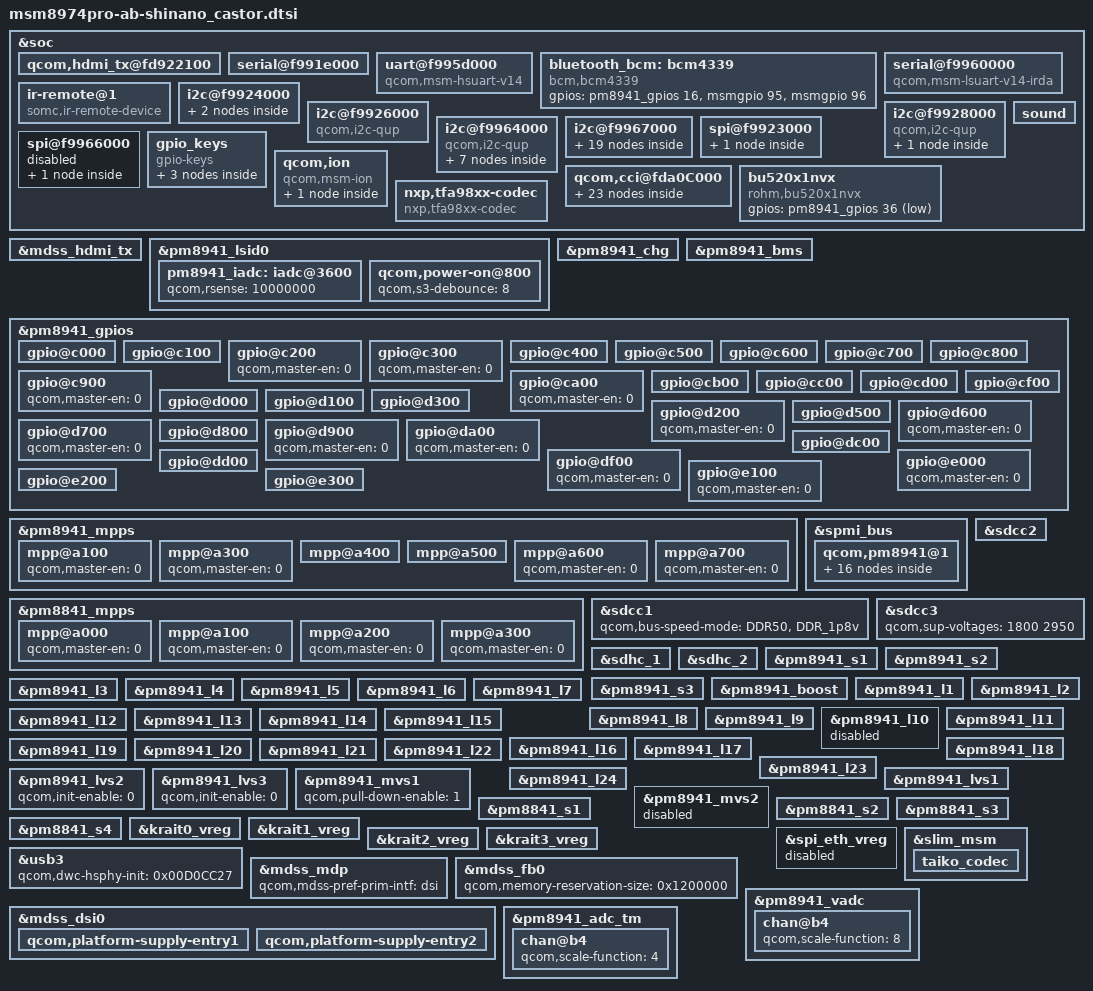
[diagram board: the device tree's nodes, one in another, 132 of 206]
/* arch/arm/boot/dts/msm8974pro-ab-shinano_castor.dtsi
 *
 * Copyright (C) 2013-2014 Sony Mobile Communications AB.
 *
 * Author: Shougo Watanabe <Shougo.X.Watanabe@sonymobile.com>
 *
 * This program is free software; you can redistribute it and/or modify
 * it under the terms of the GNU General Public License version 2 and
 * only version 2 as published by the Free Software Foundation.
 *
 * This program is distributed in the hope that it will be useful,
 * but WITHOUT ANY WARRANTY; without even the implied warranty of
 * MERCHANTABILITY or FITNESS FOR A PARTICULAR PURPOSE.  See the
 * GNU General Public License for more details.
 */

&soc {
	qcom,hdmi_tx@fd922100 {
		status = "ok";
	};

	/* UART : BLSP2 */
	serial@f991e000 {
		status = "ok";
	};

	/* UART : BLSP7 */
	uart@f995d000 {
		compatible = "qcom,msm-hsuart-v14";
		reg = <0xf995d000 0x1000>,
		<0xf9944000 0x19000>;
		reg-names = "core_mem", "bam_mem";
		interrupt-names = "core_irq", "bam_irq", "wakeup_irq";
		#address-cells = <0>;
		interrupt-parent = <&uart7>;
		interrupts = <0 1 2>;
		#interrupt-cells = <1>;
		interrupt-map-mask = <0xffffffff>;
		interrupt-map = <0 &intc 0 113 0
				 1 &intc 0 239 0
				 2 &msmgpio 42 0>;
		qcom,bam-tx-ep-pipe-index = <0>;
		qcom,bam-rx-ep-pipe-index = <1>;
		status = "ok";
	};

	bluetooth_bcm: bcm4339 {
		compatible = "bcm,bcm4339";
		gpios = <&pm8941_gpios 16 0>, /* BT_REG_ON */
			<&msmgpio 95 0>, /* BT_HOST_WAKE */
			<&msmgpio 96 0>; /* BT_DEV_WAKE */
	};

	/* UART : BLSP10 */
	serial@f9960000 {
		compatible = "qcom,msm-lsuart-v14-irda";
		reg = <0xf9960000 0x1000>;
		interrupts = <0 116 0>;
		qcom,config-gpio = <1>;
		qcom,tx-gpio = <&msmgpio 53 0x00>;
		qcom,rx-gpio = <&msmgpio 54 0x00>;
		status = "ok";
	};

	ir-remote@1 {
		compatible = "somc,ir-remote-device";
		reg = <0x1>;
		ir_remote_en = <&pm8941_mpps 5 0x00>;
		status = "ok";
	};

	/* I2C : BLSP2 */
	i2c@f9924000 {
		cell-index = <2>;
		qcom,i2c-bus-freq = <355000>;
		status = "ok";
		synaptics@20 {
			status = "disabled";
		};
		atmel_mxt_ts@4a {
			status = "disabled";
		};
	};

	/* I2C : BLSP4 */
	i2c@f9926000 {
		cell-index = <4>;
		compatible = "qcom,i2c-qup";
		reg = <0xf9926000 0x1000>;
		#address-cells = <1>;
		#size-cells = <0>;
		reg-names = "qup_phys_addr";
		interrupts = <0 98 0>;
		interrupt-names = "qup_err_intr";
		qcom,i2c-bus-freq = <355000>;
		qcom,i2c-src-freq = <50000000>;
		qcom,master-id = <86>;
		status = "ok";
	};

	/* I2C : BLSP6 */
	i2c@f9928000 {
		cell-index = <6>;
		compatible = "qcom,i2c-qup";
		reg = <0xf9928000 0x1000>;
		#address-cells = <1>;
		#size-cells = <0>;
		reg-names = "qup_phys_addr";
		interrupts = <0 100 0>;
		interrupt-names = "qup_err_intr";
		qcom,i2c-bus-freq = <355000>;
		qcom,i2c-src-freq = <50000000>;
		qcom,master-id = <86>;
		status = "ok";
		nfc@28 {
			compatible = "nxp,pn547";
			reg = <0x28>;
			interrupt-parent = <&msmgpio>;
			interrupts = <24 0x1>;
			nxp,pvdd_en = <&pm8941_gpios 34 0x01>;
			nxp,irq_gpio = <&msmgpio 24 0x00>;
			nxp,dwld_en = <&msmgpio 57 0x00>;
			nxp,ven = <&pm8941_mpps 2 0x01>;
			dynamic_config;
			configure_gpio = <&pm8941_gpios 33 0x00>;
			configure_mpp = <&pm8941_mpps 2 0x00>;
		};
	};

	/* I2C : BLSP8 */
	i2c@f9964000 {
		cell-index = <8>;
		compatible = "qcom,i2c-qup";
		reg = <0xf9964000 0x1000>;
		#address-cells = <1>;
		#size-cells = <0>;
		reg-names = "qup_phys_addr";
		interrupts = <0 102 0>;
		interrupt-names = "qup_err_intr";
		qcom,i2c-bus-freq = <355000>;
		qcom,i2c-src-freq = <50000000>;
		qcom,scl-gpio = <&msmgpio 48 0x00>;
		qcom,sda-gpio = <&msmgpio 47 0x00>;
		qcom,master-id = <84>;
		status = "ok";
		synaptics_clearpad@2c {
			compatible = "synaptics,clearpad";
			reg = <0x2c>;
			interrupt-parent = <&msmgpio>;
			interrupts = <86 0x2>;
			touch_vdd-supply = <&pm8941_l22>;
			touch_vio-supply = <&pm8941_lvs3>;
			synaptics,irq_gpio = <&msmgpio 86 0x00>;
			chip_id = <0x37>;
			num_sensor_rx = <46>;
			num_sensor_tx = <26>;
			pen_enabled = <0>;
			glove_enabled = <0>;
			touch_pressure_enabled = <1>;
			touch_size_enabled = <0>;
			touch_orientation_enabled = <0>;
			preset_x_max = <1919>;
			preset_y_max = <1199>;
			preset_n_fingers = <10>;
			por_delay_after = <200>;
			large_panel;
			wakeup_gesture_support = <1>;
			wakeup_gesture_timeout = <2000>;
			wakeup_gesture {
				double_tap {
					gesture_code = <0x0001>;
					event_00 {
						type = <2>; /* LOG */
						message = "=== DOUBLE TAP ===";
					};
					event_01 {
						type = <1>; /* KEY */
						code = <116>; /* KEY_POWER */
						down = <1>;
					};
					event_02 {
						type = <1>; /* KEY */
						code = <116>; /* KEY_POWER */
						down = <0>;
					};
					event_03 {
						type = <99>; /* END */
					};
				};
			};
		};
	};

	/* I2C : BLSP11 */
	i2c@f9967000 {
		cell-index = <11>;
		qcom,i2c-bus-freq = <355000>;
		qcom,scl-gpio = <&msmgpio 84 0x00>;
		qcom,sda-gpio = <&msmgpio 83 0x00>;
		status = "ok";
		tfa98xx_top@68 {
			compatible = "nxp,tfa98xx_top";
			reg = <0x68>;
		};
		tfa98xx_bottom@6A {
			compatible = "nxp,tfa98xx_bottom";
			reg = <0x6A>;
		};
		sii8620@72 {
			compatible = "qcom,mhl-sii8620";
			reg = <0x72>;
			interrupt-parent = <&msmgpio>;
			mhl-intr-gpio = <&msmgpio 64 0>;
			mhl-pwr-gpio = <&msmgpio 23 0>;
			mhl-rst-gpio = <&msmgpio 16 0>;
			qcom,hdmi-tx-map = <&mdss_hdmi_tx>;
			mhl-switch-sel-1-gpio = <&msmgpio 10 0>;
			mhl-switch-sel-2-gpio = <&msmgpio 11 0>;
			mhl-fw-wake-gpio =  <&msmgpio 31 0>;
		};
		ti_lp855x@2c {
			compatible = "Texas Instruments,lp855x";
			reg = <0x2c>;
			status = "ok";
			bl_enable = <&msmgpio 69 0>;
			linux,name = "lp8556";
			linux,default-trigger = "bkl-trigger";
			mode = "register based";
			chip_name = "lp8556";
			max_br = <0xff>;
			init_br = <0x3f>;
			cfg3_reg = <0x5e>;
			eprom@98 {
				addr = <0x98>;
				data = <0x16>;
			};
			eprom@9e {
				addr = <0x9e>;
				data = <0x22>;
			};
			eprom@a0 {
				addr = <0xa0>;
				data = <0xff>;
			};
			eprom@a1 {
				addr = <0xa1>;
				data = <0x3f>;
			};
			eprom@a2 {
				addr = <0xa2>;
				data = <0x20>;
			};
			eprom@a4 {
				addr = <0xa4>;
				data = <0x72>;
			};
			eprom@a5 {
				addr = <0xa5>;
				data = <0x04>;
			};
			eprom@a6 {
				addr = <0xa6>;
				data = <0x80>;
			};
			eprom@a7 {
				addr = <0xa7>;
				data = <0xf7>;
			};
			eprom@a8 {
				addr = <0xa8>;
				data = <0x24>;
			};
			eprom@a9 {
				addr = <0xa9>;
				data = <0x80>;
			};
			eprom@aa {
				addr = <0xaa>;
				data = <0x0f>;
			};
			eprom@ae {
				addr = <0xae>;
				data = <0x0f>;
			};
		};
		isa1200@48 {
			status = "disabled";
		};
		ad7146@2f {
			compatible = "AD,ad7146";
			interrupt-parent = <&spmi_bus>;
			reg = <0x2f 0>;
			interrupts = <0x0 0xc8 0x0>; /* PM8941 GPIO 9 */
			interrupt-name = "ad7146_irq_gpio";
			prox_vdd-supply = <&pm8941_l19>;
			prox_vdd-supply_name = "prox_vdd";
			AD,irq_gpio = <&pm8941_gpios 9 0x00>;
			pad,stage0-connect1 = <0x3FBF>;
			pad,stage0-connect2 = <0x1FDF>;
			pad,stage0-afe = <0x0100>;
			pad,stage0-sensitivity = <0x5454>;
			pad,stage0-offset_l = <0x000A>;
			pad,stage0-offset_h = <0x0018>;
			pad,stage0-offset_l_clamp = <0x0018>;
			pad,stage0-offset_h_clamp = <0x000A>;
			pad,stage1-connect1 = <0x37FF>;
			pad,stage1-connect2 = <0x1BFF>;
			pad,stage1-afe = <0x1200>;
			pad,stage1-sensitivity = <0x5454>;
			pad,stage1-offset_l = <0x000A>;
			pad,stage1-offset_h = <0x0070>;
			pad,stage1-offset_l_clamp = <0x0070>;
			pad,stage1-offset_h_clamp = <0x000A>;
			status = "ok";
		};
	};

	/* SPI : BLSP1 */
	spi@f9923000 {
		cs-gpios = <&msmgpio 2 0>;
		spi-max-frequency = <38400000>;
		status = "ok";
		ethernet-switch@2 {
			status = "disabled";
		};
	};

	/* SPI : BLSP10 */
	spi@f9966000 {
		status = "disabled";
		epm-adc@0 {
			status = "disabled";
		};
	};

	gpio_keys {
		compatible = "gpio-keys";
		input-name = "gpio-keys";
		interrupt-parent = <&msmgpio>;
		interrupts = <9 0>;

		vol_dn {
			label = "volume_down";
			gpios = <&pm8941_gpios 2 0x1>;
			linux,input-type = <1>;
			linux,code = <114>;
			gpio-key,wakeup;
			debounce-interval = <15>;
		};

		vol_up {
			label = "volume_up";
			gpios = <&pm8941_gpios 5 0x1>;
			linux,input-type = <1>;
			linux,code = <115>;
			gpio-key,wakeup;
			debounce-interval = <15>;
		};

		sim_det {
			label = "sim-detection";
			gpios = <&msmgpio 9 0x0>;
			linux,input-type = <5>;
			linux,code = <7>;
			gpio-key,wakeup;
			debounce-interval = <10>;
		};
	};

	qcom,cci@fda0C000 {
		qcom,cci-master0 {
			qcom,hw-thigh = <22>;
			qcom,hw-tlow = <33>;
		};

		qcom,cci-master1 {
			qcom,hw-thigh = <22>;
			qcom,hw-tlow = <33>;
		};

		qcom,camera@20 {
			compatible = "qcom,sony_camera_0";
			reg = <0x20 0x0>;
			status = "ok";
			qcom,slave-id = <0x20 0x0 0x0000>;
			qcom,csiphy-sd-index = <0>;
			qcom,csid-sd-index = <0>;
			qcom,mount-angle = <270>;
			qcom,sensor-name = "sony_camera_0";
			cam_vdig-supply = <&pm8941_l3>;
			cam_vana-supply = <&pm8941_l17>;
			cam_vio-supply = <&pm8941_lvs2>;
			cam_vaf-supply = <&pm8941_l23>;
			qcom,cam-vreg-name = "cam_vdig", "cam_vana", "cam_vio",
					     "cam_vaf";
			qcom,cam-vreg-type = <0 0 1 0>;
			qcom,cam-vreg-min-voltage = <1200000 2700000 0 2800000>;
			qcom,cam-vreg-max-voltage = <1200000 2700000 0 2800000>;
			qcom,cam-vreg-op-mode = <105000 85600 0 300000>;
			qcom,gpio-no-mux = <0>;
			gpios = <&msmgpio 15 0>,
				<&msmgpio 94 0>;
			qcom,gpio-reset = <1>;
			qcom,gpio-req-tbl-num = <0 1>;
			qcom,gpio-req-tbl-flags = <1 0>;
			qcom,gpio-req-tbl-label = "CAMIF_MCLK",
						  "CAM_RESET1";
			qcom,gpio-set-tbl-num = <1 1>;
			qcom,gpio-set-tbl-flags = <0 2>;
			qcom,gpio-set-tbl-delay = <1 1000>;
			qcom,csi-lane-assign = <0x4320>;
			qcom,csi-lane-mask = <0x1F>;
			qcom,sensor-position = <0>;
			qcom,sensor-mode = <1>;
			qcom,cci-master = <0>;
			sony,i2c_addr = <0x20>;
			sony,eeprom_addr = <0xA0>;
			sony,eeprom_type = <0>;
			sony,eeprom_max_len = <2048>;
			sony,gpio_af = <0>;
			sony,subdev_code = <0x3007>;

			sony,camera_modules {
				module_names = "GENERIC", "SOI08BS2";
				default_module_name = "SOI08BS2";

				GENERIC {
					mount_angle = <180>;
					sensor_rotation = <180>;
					sensor_facing = <0>;
					has_3a = <0>;
					pll_num = <18>;
					pll = <674 674 674 674 674 674 674 674 674 674 674 674 674 674 674 674 674 674>;
					power_off {
						commands =
								"I2C_WRITE",
								"GPIO_RESET",
								"CAM_CLK",
								"CAM_VDIG",
								"CAM_VIO",
								"CAM_VANA",
								"CAM_VAF",
								"EXIT";
						CAM_VDIG =
							<0 0xFFFFFFFF 0 1>;
						CAM_VIO = <1 0xFFFFFFFF 0 1>;
						CAM_VANA =
							<2 0xFFFFFFFF 0 1>;
						CAM_VAF = <3 0xFFFFFFFF 0 99>;
						GPIO_RESET = <5 0x0 0 1>;
						CAM_CLK = <6 0xFFFFFFFF 0 1>;
						I2C_WRITE = <7 0x0100 0 100>;
						EXIT = <8 0x0 0 0>;
					};
					power_on {
						commands =
								"CAM_VDIG",
								"CAM_VIO",
								"CAM_VANA",
								"CAM_VAF",
								"GPIO_RESET",
								"CAM_CLK",
								"EXIT";
						CAM_VDIG = <0 1200 85000 1>;
						CAM_VIO = <1 0 0 1>;
						CAM_VANA = <2 2700 103000 1>;
						CAM_VAF = <3 2800 106500 1>;
						GPIO_RESET = <5 1 0 1>;
						CAM_CLK = <6 0 0 1>;
						EXIT = <8 0x0 0 0>;
					};
				};
				SOI08BS2 {
					mount_angle = <180>;
					sensor_rotation = <180>;
					sensor_facing = <0>;
					has_3a = <0>;
					pll_num = <18>;
					pll = <674 674 674 674 674 674 674 674 674 674 674 674 674 674 674 674 674 674>;
					power_off {
						commands =
								"I2C_WRITE",
								"GPIO_RESET",
								"CAM_CLK",
								"CAM_VDIG",
								"CAM_VIO",
								"CAM_VANA",
								"CAM_VAF",
								"EXIT";
						CAM_VDIG =
							<0 0xFFFFFFFF 0 1>;
						CAM_VIO = <1 0xFFFFFFFF 0 1>;
						CAM_VANA =
							<2 0xFFFFFFFF 0 1>;
						CAM_VAF = <3 0xFFFFFFFF 0 99>;
						GPIO_RESET = <5 0x0 0 1>;
						CAM_CLK = <6 0xFFFFFFFF 0 1>;
						I2C_WRITE = <7 0x0100 0 100>;
						EXIT = <8 0x0 0 0>;
					};
					power_on {
						commands =
								"CAM_VDIG",
								"CAM_VIO",
								"CAM_VANA",
								"CAM_VAF",
								"GPIO_RESET",
								"CAM_CLK",
								"EXIT";
						CAM_VDIG = <0 1200 85000 1>;
						CAM_VIO = <1 0 0 1>;
						CAM_VANA = <2 2700 103000 1>;
						CAM_VAF = <3 2800 106500 1>;
						GPIO_RESET = <5 1 0 1>;
						CAM_CLK = <6 0 0 1>;
						EXIT = <8 0x0 0 0>;
					};
				};
			};
		};

		qcom,camera@6c {
			compatible = "qcom,sony_camera_1";
			reg = <0x6c 0x0>;
			status = "ok";
			qcom,slave-id = <0x6c 0x0000 0x0000>;
			qcom,csiphy-sd-index = <2>;
			qcom,csid-sd-index = <2>;
			qcom,mount-angle = <270>;
			qcom,sensor-name = "sony_camera_1";
			cam_vdig-supply = <&pm8941_l3>;
			cam_vana-supply = <&pm8941_l17>;
			cam_vio-supply = <&pm8941_lvs2>;
			qcom,cam-vreg-name = "cam_vdig", "cam_vana", "cam_vio";
			qcom,cam-vreg-type = <0 0 1>;
			qcom,cam-vreg-min-voltage = <1200000 2700000 0>;
			qcom,cam-vreg-max-voltage = <1200000 2700000 0>;
			qcom,cam-vreg-op-mode = <105000 85600 0>;
			qcom,gpio-no-mux = <0>;
			gpios = <&msmgpio 17 0>,
				<&msmgpio 18 0>;
			qcom,gpio-reset = <1>;
			qcom,gpio-req-tbl-num = <0 1>;
			qcom,gpio-req-tbl-flags = <1 0>;
			qcom,gpio-req-tbl-label = "CAMIF_MCLK",
						  "CAM_RESET1";
			qcom,gpio-set-tbl-num = <1 1>;
			qcom,gpio-set-tbl-flags = <0 2>;
			qcom,gpio-set-tbl-delay = <1 1000>;
			qcom,csi-lane-assign = <0x4320>;
			qcom,csi-lane-mask = <0x7>;
			qcom,sensor-position = <1>;
			qcom,sensor-mode = <1>;
			qcom,cci-master = <1>;
			sony,i2c_addr = <0x6c>;
			sony,eeprom_addr = <0xA0>;
			sony,eeprom_type = <0>;
			sony,eeprom_max_len = <1024>;
			sony,gpio_af = <0>;
			sony,subdev_code = <0x3007>;

			sony,camera_modules {
				module_names = "GENERIC", "LGI02BN1",
						"SEM02BN1";
				default_module_name = "SEM02BN1";

				GENERIC {
					mount_angle = <0>;
					sensor_rotation = <0>;
					sensor_facing = <1>;
					has_3a = <0>;
					pll_num = <18>;
					pll = <104 104 104 104 104 104 104 104 104 104 104 104 104 104 104 104 104 104>;
					power_off {
						commands =
								"I2C_WRITE",
								"GPIO_RESET",
								"CAM_CLK",
								"CAM_VANA",
								"CAM_VIO",
								"CAM_VDIG",
								"EXIT";
						CAM_VDIG =
							<0 0xFFFFFFFF 0 98>;
						CAM_VIO = <1 0xFFFFFFFF 0 1>;
						CAM_VANA =
							<2 0xFFFFFFFF 0 1>;
						GPIO_RESET = <5 0x0 0 1>;
						CAM_CLK = <6 0xFFFFFFFF 0 1>;
						I2C_WRITE = <7 0x0100 0 100>;
						EXIT = <8 0x0 0 0>;
					};
					power_on {
						commands =
								"CAM_VDIG",
								"CAM_VIO",
								"CAM_VANA",
								"GPIO_RESET",
								"CAM_CLK",
								"EXIT";
						CAM_VDIG = <0 1200 85000 1>;
						CAM_VIO = <1 0 0 1>;
						CAM_VANA = <2 2700 103000 1>;
						GPIO_RESET = <5 1 0 1>;
						CAM_CLK = <6 0 0 1>;
						EXIT = <8 0x0 0 0>;
					};
				};
				LGI02BN1 {
					mount_angle = <0>;
					sensor_rotation = <0>;
					sensor_facing = <1>;
					has_3a = <0>;
					pll_num = <18>;
					pll = <104 104 104 104 104 104 104 104 104 104 104 104 104 104 104 104 104 104>;
					power_off {
						commands =
								"I2C_WRITE",
								"GPIO_RESET",
								"CAM_CLK",
								"CAM_VANA",
								"CAM_VIO",
								"CAM_VDIG",
								"EXIT";
						CAM_VDIG =
							<0 0xFFFFFFFF 0 98>;
						CAM_VIO = <1 0xFFFFFFFF 0 1>;
						CAM_VANA =
							<2 0xFFFFFFFF 0 1>;
						GPIO_RESET = <5 0x0 0 1>;
						CAM_CLK = <6 0xFFFFFFFF 0 1>;
						I2C_WRITE = <7 0x0100 0 100>;
						EXIT = <8 0x0 0 0>;
					};
					power_on {
						commands =
								"CAM_VDIG",
								"CAM_VIO",
								"CAM_VANA",
								"GPIO_RESET",
								"CAM_CLK",
								"EXIT";
						CAM_VDIG = <0 1200 85000 1>;
						CAM_VIO = <1 0 0 1>;
						CAM_VANA = <2 2700 103000 1>;
						GPIO_RESET = <5 1 0 1>;
						CAM_CLK = <6 0 0 1>;
						EXIT = <8 0x0 0 0>;
					};
				};
				SEM02BN1 {
					mount_angle = <0>;
					sensor_rotation = <0>;
					sensor_facing = <1>;
					has_3a = <0>;
					pll_num = <18>;
					pll = <104 104 104 104 104 104 104 104 104 104 104 104 104 104 104 104 104 104>;
					power_off {
						commands =
								"I2C_WRITE",
								"GPIO_RESET",
								"CAM_CLK",
								"CAM_VANA",
								"CAM_VIO",
								"CAM_VDIG",
								"EXIT";
						CAM_VDIG =
							<0 0xFFFFFFFF 0 98>;
						CAM_VIO = <1 0xFFFFFFFF 0 1>;
						CAM_VANA =
							<2 0xFFFFFFFF 0 1>;
						GPIO_RESET = <5 0x0 0 1>;
						CAM_CLK = <6 0xFFFFFFFF 0 1>;
						I2C_WRITE = <7 0x0100 0 100>;
						EXIT = <8 0x0 0 0>;
					};
					power_on {
						commands =
								"CAM_VDIG",
								"CAM_VIO",
								"CAM_VANA",
								"GPIO_RESET",
								"CAM_CLK",
								"EXIT";
						CAM_VDIG = <0 1200 85000 1>;
						CAM_VIO = <1 0 0 1>;
						CAM_VANA = <2 2700 103000 1>;
						GPIO_RESET = <5 1 0 1>;
						CAM_CLK = <6 0 0 1>;
						EXIT = <8 0x0 0 0>;
					};
				};
			};
		};

		/* disable Qualcomm camera sensors */
		qcom,camera@6e {
			status = "disabled";
		};

		qcom,camera@90 {
			status = "disabled";
		};
	};

	qcom,ion {
		compatible = "qcom,msm-ion";

		qcom,ion-heap@20 { /* CAMERA HEAP */
			compatible = "qcom,msm-ion-reserve";
			reg = <20>;
			qcom,heap-align = <0x1000>;
			qcom,memory-reservation-type = "EBI1"; /* reserve EBI memory */
			qcom,memory-reservation-size = <0x6400000>;
			qcom,ion-heap-type = "CARVEOUT";
		};
	};

	sound {
		qcom,audio-routing =
			"RX_BIAS", "MCLK",
			"LDO_H", "MCLK",
			"AMIC5", "MCLK",
			"AMIC6", "MCLK",
			"Ext Spk Bottom Pos", "LINEOUT1",
			"Ext Spk Bottom Neg", "LINEOUT3",
			"Ext Spk Top Pos", "LINEOUT2",
			"Ext Spk Top Neg", "LINEOUT4",
			"AMIC1", "MIC BIAS1 External",
			"MIC BIAS1 External", "Secondary Mic",
			"AMIC2", "MIC BIAS2 External",
			"MIC BIAS2 External", "Headset Mic",
			"MIC BIAS2 External", "ANCRight Headset Mic",
			"AMIC3", "MIC BIAS3 External",
			"MIC BIAS3 External", "ANCLeft Headset Mic",
			"AMIC4", "MIC BIAS1 External",
			"MIC BIAS1 External", "Handset Mic";
	};

	bu520x1nvx {
		compatible = "rohm,bu520x1nvx";
		gpios = <&pm8941_gpios 36 0x1>;
	};

	nxp,tfa98xx-codec {
		compatible = "nxp,tfa98xx-codec";
	};
};

&mdss_hdmi_tx {
	/* rhine doesn't use hpd-5v */
	qcom,hdmi-tx-supply-names = "hpd-gdsc", "core-vdda", "core-vcc";
	qcom,hdmi-tx-min-voltage-level = <0 1800000 1800000>;
	qcom,hdmi-tx-max-voltage-level = <0 1800000 1800000>;
	qcom,hdmi-tx-peak-current = <0 300000 0>;
};

&pm8941_lsid0 {
	pm8941_iadc: iadc@3600 {
		qcom,rsense = <10000000>;
	};

	qcom,power-on@800 {
		qcom,s3-debounce = <8>;
	};
};

&pm8941_chg {
	qcom,vddmax-mv = <4350>;
	qcom,vddsafe-mv = <4400>;
	qcom,vinmin-mv = <4200>;
	qcom,ibatmax-ma = <3000>;
	qcom,ibatterm-ma = <300>;
	qcom,ibatsafe-ma = <3000>;
	qcom,maxinput-dc-ma = <1800>;
	qcom,maxinput-dc-mv = <10000>;
	qcom,maxinput-usb-ma = <1500>;
	qcom,maxinput-usb-mv = <13000>;
	qcom,thermal-mitigation = <3000 2500 2000 1500 1100 800 500 300 100 0>;
	qcom,cool-bat-mv = <4350>;
	qcom,ibatmax-warm-ma = <1800>;
	qcom,warm-bat-mv = <4200>;
	qcom,ibatmax-cool-ma = <1800>;
	qcom,vbatdet-delta-mv = <70>;
	qcom,tchg-mins = <512>;
	qcom,vbatweak-mv = <3200>;
};

&pm8941_bms {
	qcom,v-cutoff-uv = <3200000>;
	qcom,max-voltage-uv = <4350000>;
	qcom,r-conn-mohm = <0>;
	qcom,low-soc-calculate-soc-threshold = <5>;
	qcom,low-soc-calculate-soc-ms = <1000>;
	qcom,calculate-soc-ms = <30000>;
	qcom,chg-term-ua = <300000>;
	qcom,use-external-rsense;
	qcom,batt-type = <3>;
	qcom,use-ocv-thresholds;
	qcom,ocv-voltage-high-threshold-uv = <3830000>;
	qcom,ocv-voltage-low-threshold-uv = <3740000>;
	qcom,shutdown-soc-valid-limit = <40>;
	qcom,enable-fcc-learning;
	qcom,min-fcc-learning-soc = <20>;
	qcom,min-fcc-ocv-pc = <30>;
	qcom,min-fcc-learning-samples = <5>;
	qcom,fcc-resolution = <26>;
	qcom,clamp-soc-max-count = <2>;
};

&pm8941_gpios {
	/* GPIO_1: CHG_PATH_PRI */
	gpio@c000 {
		qcom,src-sel = <0>;		/* GPIO */
		qcom,mode = <0>;		/* In */
		qcom,vin-sel = <2>;		/* S3 */
		qcom,pull = <5>;		/* NP */
		qcom,master-en = <1>;		/* Enable */
		status = "ok";
	};

	/* GPIO_2: VOL_DN */
	gpio@c100 {
		qcom,src-sel = <0>;		/* GPIO */
		qcom,mode = <0>;		/* In */
		qcom,vin-sel = <2>;		/* S3 */
		qcom,pull = <0>;		/* PU */
		qcom,master-en = <1>;		/* Enable */
		status = "ok";
	};

	/* GPIO_3: NC */
	gpio@c200 {
		qcom,master-en = <0>;		/* Disable */
		status = "ok";
	};

	/* GPIO_4: NC */
	gpio@c300 {
		qcom,master-en = <0>;		/* Disable */
		status = "ok";
	};

	/* GPIO_5: VOL_UP */
	gpio@c400 {
		qcom,src-sel = <0>;		/* GPIO */
		qcom,mode = <0>;		/* In */
		qcom,vin-sel = <2>;		/* S3 */
		qcom,pull = <0>;		/* PU */
		qcom,master-en = <1>;		/* Enable */
		status = "ok";
	};

	/* GPIO_6: HW_ID_1 */
	gpio@c500 {
		qcom,src-sel = <0>;		/* GPIO */
		qcom,mode = <0>;		/* In */
		qcom,vin-sel = <2>;		/* S3 */
		qcom,pull = <5>;		/* NP */
		qcom,master-en = <1>;		/* Enable */
		status = "ok";
	};

	/* GPIO_7: HW_ID_2 */
	gpio@c600 {
		qcom,src-sel = <0>;		/* GPIO */
		qcom,mode = <0>;		/* In */
		qcom,vin-sel = <2>;		/* S3 */
		qcom,pull = <5>;		/* NP */
		qcom,master-en = <1>;		/* Enable */
		status = "ok";
	};

	/* GPIO_8: RF_LCD_ID_EN */
	gpio@c700 {
		qcom,src-sel = <0>;		/* GPIO */
		qcom,mode = <1>;		/* Out */
		qcom,output-type = <0>;		/* CMOS */
		qcom,vin-sel = <2>;		/* S3 */
		qcom,out-strength = <3>;	/* High */
		qcom,invert = <0>;		/* Low */
		qcom,master-en = <1>;		/* Enable */
		status = "ok";
	};

	/* GPIO_9: P_SENSOR_INT_N */
	gpio@c800 {
		qcom,src-sel = <0>;		/* GPIO */
		qcom,mode = <0>;		/* In */
		qcom,vin-sel = <2>;		/* S3 */
		qcom,pull = <0>;		/* PU */
		qcom,master-en = <1>;		/* Enable */
		status = "ok";
	};

	/* GPIO_10: NC (P_SENSOR_INT2_N) */
	gpio@c900 {
		qcom,master-en = <0>;		/* Disable */
		status = "ok";
	};

	/* GPIO_11: NC (FCHG_I2C_PU) */
	gpio@ca00 {
		qcom,master-en = <0>;		/* Disable */
		status = "ok";
	};

	/* GPIO_12: RF_ID_EXTENTION */
	gpio@cb00 {
		qcom,src-sel = <0>;		/* GPIO */
		qcom,mode = <0>;		/* In */
		qcom,vin-sel = <2>;		/* S3 */
		qcom,pull = <4>;		/* PD */
		qcom,master-en = <1>;		/* Enable */
		status = "ok";
	};

	/* GPIO_13: DAMP_RESET */
	gpio@cc00 {
		qcom,src-sel = <0>;		/* GPIO */
		qcom,mode = <1>;		/* Out */
		qcom,output-type = <0>;		/* CMOS */
		qcom,vin-sel = <2>;		/* S3 */
		qcom,out-strength = <1>;	/* Low */
		qcom,invert = <0>;		/* Low */
		qcom,master-en = <1>;		/* Enable */
		status = "ok";
	};

	/* GPIO_14: HW_ID_3 */
	gpio@cd00 {
		qcom,src-sel = <0>;		/* GPIO */
		qcom,mode = <0>;		/* In */
		qcom,vin-sel = <2>;		/* S3 */
		qcom,pull = <5>;		/* NP */
		qcom,master-en = <1>;		/* Enable */
		status = "ok";
	};

	/* GPIO_15: DIVCLK1_CODEC */
	/* Follow QCT */

	/* GPIO_16: BT_REG_ON */
	gpio@cf00 {
		qcom,src-sel = <0>;		/* GPIO */
		qcom,mode = <1>;		/* Out */
		qcom,output-type = <0>;		/* CMOS */
		qcom,vin-sel = <2>;		/* S3 */
		qcom,out-strength = <1>;	/* Low */
		qcom,invert = <0>;		/* Low */
		qcom,master-en = <1>;		/* Enable */
		status = "ok";
	};

	/* GPIO_17: WL_SLEEP_CLK */
	gpio@d000 {
		qcom,src-sel = <3>;		/* Alternate function 2 */
		qcom,mode = <1>;		/* Out */
		qcom,output-type = <0>;		/* CMOS */
		qcom,vin-sel = <2>;		/* S3 */
		qcom,out-strength = <1>;	/* Low */
		qcom,invert = <0>;		/* Low */
		qcom,master-en = <1>;		/* Enable */
		status = "ok";
	};

	/* GPIO_18: WL_REG_ON */
	gpio@d100 {
		qcom,src-sel = <0>;		/* GPIO */
		qcom,mode = <1>;		/* Out */
		qcom,output-type = <0>;		/* CMOS */
		qcom,vin-sel = <2>;		/* S3 */
		qcom,out-strength = <1>;	/* Low */
		qcom,invert = <0>;		/* Low */
		qcom,master-en = <1>;		/* Enable */
		status = "ok";
	};

	/* GPIO_19: NC (DISP_RESET_N) */
	gpio@d200 {
		qcom,master-en = <0>;		/* Disable */
		status = "ok";
	};

	/* GPIO_20: LCD_DCDC_EN */
	gpio@d300 {
		qcom,src-sel = <0>;		/* GPIO */
		qcom,mode = <1>;		/* Out */
		qcom,output-type = <0>;		/* CMOS */
		qcom,vin-sel = <2>;		/* S3 */
		qcom,out-strength = <1>;	/* Low */
		qcom,invert = <0>;		/* Low */
		qcom,master-en = <1>;		/* Enable */
		somc,keep_high_at_init;
		status = "ok";
	};

	/* GPIO_21: BOOST_BYP_EN */
	/* Follow QCT */

	/* GPIO_22: DAMP_INT */
	gpio@d500 {
		qcom,src-sel = <0>;		/* GPIO */
		qcom,mode = <0>;		/* In */
		qcom,vin-sel = <2>;		/* S3 */
		qcom,pull = <5>;		/* NP */
		qcom,master-en = <1>;		/* Enable */
		status = "ok";
	};

	/* GPIO_23: NC (NFC_VEN_FELICA_PON) */
	gpio@d600 {
		qcom,master-en = <0>;		/* Disable */
		status = "ok";
	};

	/* GPIO_24: NC (NFC_EXT_LDO_EN) */
	gpio@d700 {
		qcom,master-en = <0>;		/* Disable */
		status = "ok";
	};

	/* GPIO_25: P_SENSE_CNTL */
	gpio@d800 {
		qcom,src-sel = <0>;		/* GPIO */
		qcom,mode = <1>;		/* Out */
		qcom,output-type = <1>;		/* OpenDrain NMOS */
		qcom,vin-sel = <0>;		/* VPH */
		qcom,out-strength = <1>;	/* Low */
		qcom,invert = <1>;		/* High */
		qcom,master-en = <1>;		/* Enable */
		status = "ok";
	};

	/* GPIO_26: NC (TUNER_ANT_SW_EN) */
	gpio@d900 {
		qcom,master-en = <0>;		/* Disable */
		status = "ok";
	};

	/* GPIO_27: NC */
	gpio@da00 {
		qcom,master-en = <0>;		/* Disable */
		status = "ok";
	};

	/* GPIO_28: TX_GTR_THRES */
	/* Follow QCT */

	/* GPIO_29: DAMP2_RESET */
	gpio@dc00 {
		qcom,src-sel = <0>;		/* GPIO */
		qcom,mode = <1>;		/* Out */
		qcom,output-type = <0>;		/* CMOS */
		qcom,vin-sel = <2>;		/* S3 */
		qcom,out-strength = <1>;	/* Low */
		qcom,invert = <0>;		/* Low */
		qcom,master-en = <1>;		/* Enable */
		status = "ok";
	};

	/* GPIO_30: DAMP2_INT */
	gpio@dd00 {
		qcom,src-sel = <0>;		/* GPIO */
		qcom,mode = <0>;		/* In */
		qcom,vin-sel = <2>;		/* S3 */
		qcom,pull = <5>;		/* NP */
		qcom,master-en = <1>;		/* Enable */
		status = "ok";
	};

	/* GPIO_31: BATT_REM_ALERM */
	/* Follow QCT */

	/* GPIO_32: NC (TUNER_ANT_SW1) */
	gpio@df00 {
		qcom,master-en = <0>;		/* Disable */
		status = "ok";
	};

	/* GPIO_33: NC (FELICA_FF) */
	gpio@e000 {
		qcom,master-en = <0>;		/* Disable */
		status = "ok";
	};

	/* GPIO_34: NC (FELICA_PVDD_EN) */
	gpio@e100 {
		qcom,master-en = <0>;		/* Disable */
		status = "ok";
	};

	/* GPIO_35: NFC_CLK_REQ */
	gpio@e200 {
		qcom,src-sel = <0>;		/* GPIO */
		qcom,mode = <0>;		/* In */
		qcom,vin-sel = <2>;		/* S3 */
		qcom,pull = <4>;		/* PD */
		qcom,master-en = <1>;		/* Enable */
		status = "ok";
	};

	/* GPIO_36: ACC_COVER_OPEN */
	gpio@e300 {
		qcom,src-sel = <0>;		/* GPIO */
		qcom,mode = <0>;		/* In */
		qcom,vin-sel = <2>;		/* S3 */
		qcom,pull = <0>;		/* PU */
		qcom,master-en = <1>;		/* Enable */
		status = "ok";
	};
};

&pm8941_mpps {
	/* MPP_1: SDC_UIM_VBIAS */
	/* Follow QCT */

	/* MPP_2: NFC_VEN */
	mpp@a100 {
		qcom,master-en = <0>;		/* Disable */
		status = "ok";
	};

	/* MPP_3: TXDAC0_VREF */
	/* Follow QCT */

	/* MPP_4: NC (WPC_THERM) */
	mpp@a300 {
		qcom,master-en = <0>;		/* Disable */
		status = "ok";
	};

	/* MPP_5: IR_REMOTE_EN */
	mpp@a400 {
		qcom,src-sel = <0>;		/* GPIO */
		qcom,mode = <1>;		/* DOUT */
		qcom,vin-sel = <2>;		/* S3 */
		qcom,invert = <0>;		/* Low */
		qcom,master-en = <1>;		/* Enable */
		status = "ok";
	};

	/* MPP_6: LCD_ID_ADC */
	mpp@a500 {
		qcom,mode = <4>;		/* AIN */
		qcom,ain-route = <1>;		/* AMUX 6 */
		qcom,master-en = <1>;		/* Enable */
		status = "ok";
	};

	/* MPP_7: RF_ID */
	mpp@a600 {
		qcom,master-en = <0>;		/* Disable */
		status = "ok";
	};

	/* MPP_8: NC (VBAT_M) */
	mpp@a700 {
		qcom,master-en = <0>;		/* Disable */
		status = "ok";
	};
};

&pm8841_mpps {
	/* MPP_1: NC (DNC_LDO_EN) */
	mpp@a000 {
		qcom,master-en = <0>;		/* Disable */
		status = "ok";
	};

	/* MPP_2: NC (FLASH_DR_RST_N) */
	mpp@a100 {
		qcom,master-en = <0>;		/* Disable */
		status = "ok";
	};

	/* MPP_3: NC (TUNER_STATUS0) (TUNER_ANT_SW2) */
	mpp@a200 {
		qcom,master-en = <0>;		/* Disable */
		status = "ok";
	};

	/* MPP_4: NC (TUNER_STATUS1) (TUNER_ANT_SW3) */
	mpp@a300 {
		qcom,master-en = <0>;		/* Disable */
		status = "ok";
	};
};

&spmi_bus {
	qcom,pm8941@1 {
		qcom,vib@c000 {
			status = "okay";
			compatible = "qcom,qpnp-vibrator";
			reg = <0xc000 0x100>;
			label = "vibrator";
			qcom,qpnp-vib-vtg-level-mV = <3100>;
		};

		qcom,vibrator@c100 {
			status = "disabled";
		};

		qcom,vibrator@c200 {
			status = "disabled";
		};

		qcom,vibrator@c300 {
			status = "disabled";
		};

		qcom,vibrator@c400 {
			status = "disabled";
		};

		qcom,vibrator@c500 {
			status = "disabled";
		};

		qcom,vibrator@c600 {
			status = "disabled";
		};

		qcom,vibrator@c700 {
			status = "disabled";
		};
	};
};

&sdcc1 {
	qcom,bus-speed-mode = "DDR50", "DDR_1p8v";
};

&sdcc2 {
	qcom,bus-speed-mode = "SDR12", "SDR25", "SDR50", "DDR50";
	qcom,current-limit = <400>;
	qcom,pad-drv-on = <0x7 0x2 0x2>; /* 16mA, 6mA, 6mA */
};

&sdcc3 {
	qcom,sup-voltages = <1800 2950>;
	status = "ok";
};

&sdhc_1 {
	qcom,clk-rates = <400000 20000000 25000000 50000000 100000000>;
	qcom,bus-speed-mode = "DDR_1p8v";
	qcom,pad-drv-on = <0x7 0x4 0x4>; /* 16mA, 10mA, 10mA */
};

&sdhc_2 {
	qcom,vdd-current-level = <400000 400000>;
	qcom,pad-drv-on = <0x7 0x2 0x2>; /* 16mA, 6mA, 6mA */
};

&spmi_bus {
	qcom,pm8941@1 {
		qcom,leds@d800 {
			status = "disabled";
			qcom,wled_0 {
				label = "wled";
				linux,name = "wled:backlight";
				linux,default-trigger = "bkl-trigger";
				qcom,cs-out-en = <1>;
				qcom,cabc-en = <0>;
				qcom,op-fdbck = <0>;
				qcom,default-state = "on";
				qcom,max-current = <20>;
				qcom,ctrl-delay-us = <0>;
				qcom,boost-curr-lim = <3>;
				qcom,cp-sel = <0>;
				qcom,switch-freq = <2>;
				qcom,ovp-val = <2>;
				qcom,num-strings = <2>;
				qcom,id = <0>;
			};
		};

		qcom,leds@d000 {
			status = "okay";
			qcom,rgb_sync = <1>;

			qcom,rgb_0 {
				label = "rgb";
				linux,name = "led:rgb_red";
				qcom,mode = "pwm";
				qcom,pwm-channel = <6>;
				qcom,pwm-us = <1000>;
				qcom,pwm-max-value = <74>;
				qcom,max-current = <12>;
				qcom,default-state = "off";
				qcom,id = <3>;
				linux,default-trigger = "none";
			};

			qcom,rgb_1 {
				label = "rgb";
				linux,name = "led:rgb_green";
				qcom,mode = "pwm";
				qcom,pwm-channel = <5>;
				qcom,pwm-us = <1000>;
				qcom,pwm-max-value = <70>;
				qcom,max-current = <12>;
				qcom,default-state = "off";
				qcom,id = <4>;
				linux,default-trigger = "none";
			};

			qcom,rgb_2 {
				label = "rgb";
				linux,name = "led:rgb_blue";
				qcom,mode = "pwm";
				qcom,pwm-channel = <4>;
				qcom,pwm-us = <1000>;
				qcom,pwm-max-value = <40>;
				qcom,max-current = <12>;
				qcom,default-state = "off";
				qcom,id = <5>;
				linux,default-trigger = "none";
			};
		};

		qcom,leds@d300 {
			status = "disabled";
		};

		qcom,leds@e200 {
			status = "disabled";
		};
	};
};

/* Regulator config */
&pm8941_s1 {
	status = "ok";
};

&pm8941_s2 {
	status = "ok";
};

&pm8941_s3 {
	status = "ok";
};

&pm8941_boost { /* VREG_5V */
	regulator-min-microvolt = <5100000>;
	regulator-max-microvolt = <5100000>;
	status = "ok";
};

&pm8941_l1 {
	status = "ok";
};

&pm8941_l2 {
	status = "ok";
};

&pm8941_l3 {
	regulator-min-microvolt = <1200000>;
	regulator-max-microvolt = <1200000>;
	qcom,init-enable = <0>;
	qcom,init-voltage = <1200000>;
	status = "ok";
};

&pm8941_l4 {
	status = "ok";
};

&pm8941_l5 {
	status = "ok";
};

&pm8941_l6 {
	status = "ok";
};

&pm8941_l7 {
	status = "ok";
};

&pm8941_l8 {
	status = "ok";
};

&pm8941_l9 {
	status = "ok";
};

&pm8941_l10 {
	status = "disabled";
};

&pm8941_l11 {
	status = "ok";
};

&pm8941_l12 {
	status = "ok";
};

&pm8941_l13 {
	status = "ok";
};

&pm8941_l14 {
	status = "ok";
};

&pm8941_l15 {
	status = "ok";
};

&pm8941_l16 {
	status = "ok";
};

&pm8941_l17 {
	regulator-min-microvolt = <2700000>;
	regulator-max-microvolt = <2700000>;
	qcom,init-enable = <0>;
	qcom,init-voltage = <2700000>;
	status = "ok";
};

&pm8941_l18 {
	regulator-min-microvolt = <2850000>;
	regulator-max-microvolt = <2850000>;
	regulator-always-on;
	qcom,init-enable = <0>;
	qcom,init-voltage = <2850000>;
	status = "ok";
};

&pm8941_l19 {
	regulator-min-microvolt = <2850000>;
	regulator-max-microvolt = <2850000>;
	qcom,init-voltage = <2850000>;
	status = "ok";
};

&pm8941_l20 {
	regulator-min-microvolt = <2950000>;
	regulator-max-microvolt = <2950000>;
	qcom,init-voltage = <2950000>;
	status = "ok";
};

&pm8941_l21 {
	regulator-min-microvolt = <2950000>;
	regulator-max-microvolt = <2950000>;
	qcom,init-voltage = <2950000>;
	status = "ok";
};

&pm8941_l22 {
	regulator-min-microvolt = <3000000>;
	regulator-max-microvolt = <3000000>;
	qcom,init-enable = <0>;
	qcom,init-voltage = <3000000>;
	status = "ok";
};

&pm8941_l23 {
	regulator-min-microvolt = <2800000>;
	regulator-max-microvolt = <2800000>;
	qcom,init-enable = <0>;
	qcom,init-voltage = <2800000>;
	status = "ok";
};

&pm8941_l24 {
	status = "ok";
};

&pm8941_lvs1 {
	regulator-always-on;
	qcom,init-enable = <0>;
	status = "ok";
};

&pm8941_lvs2 {
	qcom,init-enable = <0>;
	status = "ok";
};

&pm8941_lvs3 {
	qcom,init-enable = <0>;
	status = "ok";
};

&pm8941_mvs1 { /* VREG_OTG */
	qcom,pull-down-enable = <1>;
	status = "ok";
};

&pm8941_mvs2 { /* VREG_HDMI */
	status = "disabled";
};

&pm8841_s1 {
	status = "ok";
};

&pm8841_s2 {
	status = "ok";
};

&pm8841_s3 {
	status = "ok";
};

&pm8841_s4 {
	status = "ok";
};

&krait0_vreg { /* PM8821 VREG_S5 */
	status = "ok";
};

&krait1_vreg { /* PM8821 VREG_S6 */
	status = "ok";
};

&krait2_vreg { /* PM8821 VREG_S7 */
	status = "ok";
};

&krait3_vreg { /* PM8821 VREG_S8 */
	status = "ok";
};

&spi_eth_vreg {
	status = "disabled";
};

&slim_msm {
	taiko_codec {
		qcom,cdc-micbias-ldoh-v = <0x3>;
		qcom,cdc-micbias-cfilt1-mv = <2700>;
		qcom,cdc-micbias-cfilt2-mv = <2700>;
		qcom,cdc-micbias-cfilt3-mv = <2700>;
		qcom,cdc-micbias1-cfilt-sel = <0x0>;
		qcom,cdc-micbias2-cfilt-sel = <0x1>;
		qcom,cdc-micbias3-cfilt-sel = <0x2>;
		qcom,cdc-micbias4-cfilt-sel = <0x0>;
	};
};

&usb3 {
	qcom,dwc-hsphy-init = <0x00D0CC27>;
};

&mdss_mdp {
	qcom,mdss-pref-prim-intf = "dsi";
};

&mdss_fb0 {
	qcom,memory-reservation-size = <0x1200000>; /* size 19MB */
};

&mdss_dsi0 {
	qcom,dsi-pref-prim-pan = <&dsi_default_gpio_0>;
	vdd-supply = <>;
	qcom,platform-enable-gpio = <&pm8941_gpios 20 0>;
	qcom,platform-lane-config = [];
	qcom,platform-supply-entry1 {
			qcom,supply-name = "vddio";
			qcom,supply-min-voltage = <1800000>;
			qcom,supply-max-voltage = <1800000>;
			qcom,supply-enable-load = <100000>;
			qcom,supply-disable-load = <100>;
			qcom,supply-pre-on-sleep = <0>;
			qcom,supply-post-on-sleep = <0>;
			qcom,supply-pre-off-sleep = <0>;
			qcom,supply-post-off-sleep = <0>;
	};
	qcom,platform-supply-entry2 {
			qcom,supply-name = "vdda";
			qcom,supply-min-voltage = <1200000>;
			qcom,supply-max-voltage = <1200000>;
			qcom,supply-enable-load = <100000>;
			qcom,supply-disable-load = <100>;
			qcom,supply-pre-on-sleep = <0>;
			qcom,supply-post-on-sleep = <0>;
			qcom,supply-pre-off-sleep = <0>;
			qcom,supply-post-off-sleep = <0>;
	};
};

&pm8941_vadc {
	chan@b4 {
		qcom,scale-function = <8>;
	};
};

&pm8941_adc_tm {
	chan@b4 {
		qcom,scale-function = <4>;
	};
};
